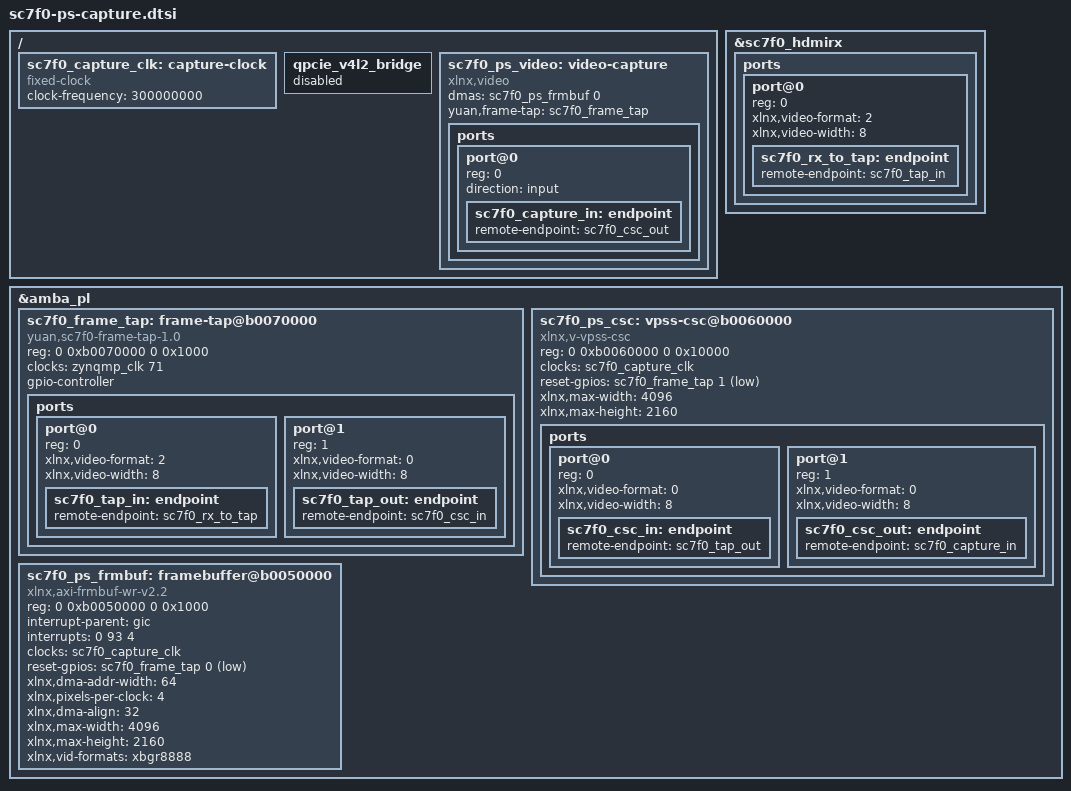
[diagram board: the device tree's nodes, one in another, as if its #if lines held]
/* ONLY for official-capture hardware0x26102801+: new apertures/IRQ/reset ABI.
 * Never enable on26102702/26102703. Imported XSA and BOOT must match.
 */
#include <dt-bindings/gpio/gpio.h>
/* Stable DT enums from2023.2 xilinx-vip.h: RBG=2, YUV_420=3.
 * DTG's standalone include tree does not ship that kernel-only header. */
/ {
	/* Physical Si5341 OUT8=300MHz / BUFGCE_DIV1, independent of PCIe. */
	sc7f0_capture_clk: capture-clock {
		compatible = "fixed-clock";
		#clock-cells = <0>;
		clock-frequency = <300000000>;
	};
	/* VIPP becomes the sole master binding the HDMI RX subdevice. */
	qpcie_v4l2_bridge { status = "disabled"; };
	sc7f0_ps_video: video-capture {
		compatible = "xlnx,video";
		dmas = <&sc7f0_ps_frmbuf 0>;
		dma-names = "port0";
		yuan,frame-tap = <&sc7f0_frame_tap>;
		status = "okay";
		ports {
			#address-cells = <1>;
			#size-cells = <0>;
			port@0 {
				reg = <0>;
				direction = "input";
				sc7f0_capture_in: endpoint { remote-endpoint = <&sc7f0_csc_out>; };
			};
		};
	};

};
&sc7f0_hdmirx {
	ports {
		#address-cells = <1>;
		#size-cells = <0>;
		port@0 {
			reg = <0>;
			xlnx,video-format = <2>;
			xlnx,video-width = <8>;
			sc7f0_rx_to_tap: endpoint { remote-endpoint = <&sc7f0_tap_in>; };
		};
	};
};
&amba_pl {
	sc7f0_frame_tap: frame-tap@b0070000 {
		compatible = "yuan,sc7f0-frame-tap-1.0";
		reg = <0 0xb0070000 0 0x1000>;
		clocks = <&zynqmp_clk 71>; /* CSR100MHz; timestamp rate is150MHz. */
		status = "okay";
		gpio-controller;
		#gpio-cells = <2>;
		ports {
			#address-cells = <1>;
			#size-cells = <0>;
			port@0 {
				reg = <0>;
				xlnx,video-format = <2>;
				xlnx,video-width = <8>;
				sc7f0_tap_in: endpoint { remote-endpoint = <&sc7f0_rx_to_tap>; };
			};
			port@1 {
				reg = <1>;
				/* Label follows the CSC (see sc7f0_ps_csc port@0): RGB under
				 * the RGB personality, YCbCr 4:2:2 otherwise.  A mismatch here
				 * only mislabels the graph, but a mislabelled graph is exactly
				 * what makes a colour-cast bug look like a driver bug.
				 */
#if defined(SC7F0_RGB_COMPOSITOR_ENABLE) && SC7F0_RGB_COMPOSITOR_ENABLE && (!defined(SC7F0_VCU_ENABLE) || !SC7F0_VCU_ENABLE)
				xlnx,video-format = <0>;
#else
				xlnx,video-format = <2>;
#endif
				xlnx,video-width = <8>;
				sc7f0_tap_out: endpoint { remote-endpoint = <&sc7f0_csc_in>; };
			};
		};
	};
	sc7f0_ps_csc: vpss-csc@b0060000 {
		compatible = "xlnx,v-vpss-csc";
		reg = <0 0xb0060000 0 0x10000>;
		clocks = <&sc7f0_capture_clk>;
		reset-gpios = <&sc7f0_frame_tap 1 GPIO_ACTIVE_LOW>;
		xlnx,max-width = <4096>;
		xlnx,max-height = <2160>;
		status = "okay";
		ports {
			#address-cells = <1>;
			#size-cells = <0>;
			port@0 {
				reg = <0>;
				/* drivers/media/platform/xilinx/xilinx-vpss-csc.c numbers the
				 * colour spaces RGB=0, YCRCB_444=1, YCRCB_422=2, YCRCB_420=3.
				 * The shipped capture persona takes YCbCr 4:2:2 from the tap and
				 * puts YCbCr 4:2:0 (NV12) in DDR.  Under the RGB personality the
				 * writer takes RGBX, so the CSC has to leave the pixels as RGB:
				 * both ends become 0 and the driver runs its RGB->RGB path
				 * (xilinx-vpss-csc.c defaults cft_in/cft_out to XVIDC_CSF_RGB).
				 * If a source turns out to be YCbCr rather than RGB, the fix is
				 * this pair of values (in 1 or 2, out 0), not a fabric change;
				 * scripts/audit_sc7f0_rgb_compositor_image.sh is what decides it.
				 */
#if defined(SC7F0_RGB_COMPOSITOR_ENABLE) && SC7F0_RGB_COMPOSITOR_ENABLE && (!defined(SC7F0_VCU_ENABLE) || !SC7F0_VCU_ENABLE)
				xlnx,video-format = <0>;
#else
				xlnx,video-format = <2>;
#endif
				xlnx,video-width = <8>;
				sc7f0_csc_in: endpoint { remote-endpoint = <&sc7f0_tap_out>; };
			};
			port@1 {
				reg = <1>;
#if defined(SC7F0_RGB_COMPOSITOR_ENABLE) && SC7F0_RGB_COMPOSITOR_ENABLE && (!defined(SC7F0_VCU_ENABLE) || !SC7F0_VCU_ENABLE)
				xlnx,video-format = <0>;
#else
				xlnx,video-format = <3>;
#endif
				xlnx,video-width = <8>;
				sc7f0_csc_out: endpoint { remote-endpoint = <&sc7f0_capture_in>; };
			};
		};
	};
	sc7f0_ps_frmbuf: framebuffer@b0050000 {
		compatible = "xlnx,axi-frmbuf-wr-v2.2";
		reg = <0 0xb0050000 0 0x1000>;
		#dma-cells = <1>;
		interrupt-parent = <&gic>;
		interrupts = <0 93 4>; /* PL IRQ0[4], level high. */
		clocks = <&sc7f0_capture_clk>;
		clock-names = "ap_clk";
		reset-gpios = <&sc7f0_frame_tap 0 GPIO_ACTIVE_LOW>;
		xlnx,dma-addr-width = <64>;
		xlnx,pixels-per-clock = <4>;
		xlnx,dma-align = <32>;
		xlnx,max-width = <4096>;
		xlnx,max-height = <2160>;
		/* A1 (round 26111602): under the RGB compositor personality this buffer IS
		 * the compositor's Plane A, and Plane A is DRM_FORMAT_ABGR8888 (AB24),
		 * whose memory bytes are R,G,B,A.  The IP is built with HAS_RGBX8, and the
		 * driver's own table in drivers/dma/xilinx/xilinx_frmbuf.c pairs
		 *   "xbgr8888" -> XILINX_FRMBUF_FMT_RGBX8 -> DRM_FORMAT_XBGR8888 -> R,G,B,X
		 *   "xrgb8888" -> XILINX_FRMBUF_FMT_BGRX8 -> DRM_FORMAT_XRGB8888 -> B,G,R,X
		 * so "xbgr8888" is the only string here that is byte-compatible with the
		 * plane that reads it; "xrgb8888" would reach the HDMI output with red and
		 * blue exchanged.  One format on purpose: the driver must have exactly one
		 * format to negotiate on this node.
		 */
#if defined(SC7F0_RGB_COMPOSITOR_ENABLE) && SC7F0_RGB_COMPOSITOR_ENABLE && (!defined(SC7F0_VCU_ENABLE) || !SC7F0_VCU_ENABLE)
		xlnx,vid-formats = "xbgr8888";
#else
		xlnx,vid-formats = "nv12";
#endif
		status = "okay";
	};
};
